# S32K146_M4 register map
Vendor: NXP Semiconductors; File version: 1.0
CPU: CM4 r0p1, little endian, MPU, FPU, VTOR, 4 interrupt priority bits
Registers are 32-bit, read-write, reset 0x0 unless marked. A register's access mark holds for its fields unless they carry their own. Offsets are from the block's base; [hi:lo] are bit positions; {n}, {i} and the like mark numbered series.

## FLEXCAN2 — CAN
Base 0x4002B000
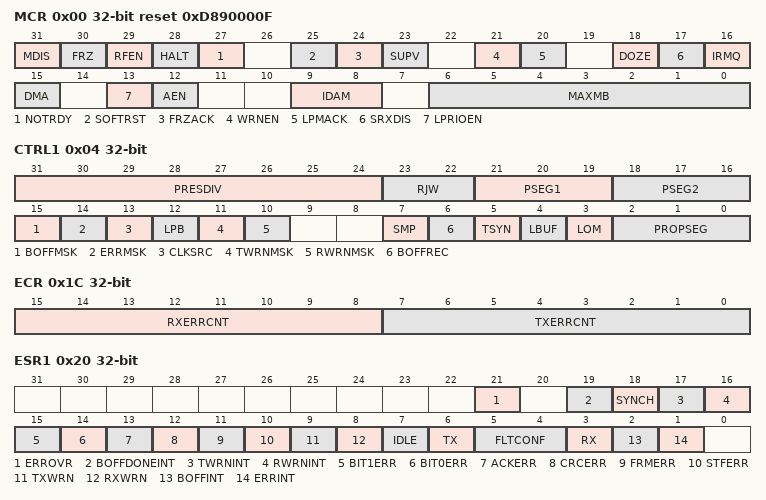
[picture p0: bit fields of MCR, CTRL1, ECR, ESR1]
0x00 MCR reset 0xD890000F — Module Configuration register
  [31] MDIS — Module Disable
    0=flexcan_enabled (Enable the FlexCAN module.); 1=flexcan_disabled (Disable the FlexCAN module.)
  [30] FRZ — Freeze Enable
    0=freeze_mode_disabled (Not enabled to enter Freeze mode.); 1=freeze_mode_enabled (Enabled to enter Freeze mode.)
  [29] RFEN — Rx FIFO Enable
    0=id2 (Rx FIFO not enabled.); 1=id4 (Rx FIFO enabled.)
  [28] HALT — Halt FlexCAN
    0=HALT_disable (No Freeze mode request.); 1=HALT_enable (Enters Freeze mode if the FRZ bit is asserted.)
  [27] NOTRDY ro — FlexCAN Not Ready
    0=id1 (FlexCAN module is either in Normal mode, Listen-Only mode, or Loop-Back mode.); 1=id2 (FlexCAN module is either in Disable mode, Doze mode, Stop mode, or Freeze mode.)
  [25] SOFTRST — Soft Reset
    0=SOFTRST_no_reset_request (No reset request.); 1=SOFTRST_reset_registers (Resets the registers affected by soft reset.)
  [24] FRZACK ro — Freeze Mode Acknowledge
    0=freeze_mode_no (FlexCAN not in Freeze mode, prescaler running.); 1=freeze_mode_yes (FlexCAN in Freeze mode, prescaler stopped.)
  [23] SUPV — Supervisor Mode
    0=id2 (FlexCAN is in User mode. Affected registers allow both Supervisor and Unrestricted accesses.); 1=id4 (FlexCAN is in Supervisor mode. Affected registers allow only Supervisor access. Unrestricted access behaves as though the access was done to an unimplemented register location.)
  [21] WRNEN — Warning Interrupt Enable
    0=TWRNINT_RWRNINT_inactive (TWRNINT and RWRNINT bits are zero, independent of the values in the error counters.); 1=TWRNINT_RWRNINT_active (TWRNINT and RWRNINT bits are set when the respective error counter transitions from less than 96 to greater than or equal to 96.)
  [20] LPMACK ro — Low-Power Mode Acknowledge
    0=low_power_no (FlexCAN is not in a low-power mode.); 1=low_power_yes (FlexCAN is in a low-power mode.)
  [18] DOZE — Doze Mode Enable
    0=low_power_doze_disabled (FlexCAN is not enabled to enter low-power mode when Doze mode is requested.); 1=low_power_doze_enabled (FlexCAN is enabled to enter low-power mode when Doze mode is requested.)
  [17] SRXDIS — Self Reception Disable
    0=self_reception_enabled; 1=self_reception_disabled
  [16] IRMQ — Individual Rx Masking And Queue Enable
    0=individual_rx_masking_disabled (Individual Rx masking and queue feature are disabled. For backward compatibility with legacy applications, the reading of C/S word locks the MB even if it is EMPTY.); 1=individual_rx_masking_enabled (Individual Rx masking and queue feature are enabled.)
  [15] DMA — DMA Enable
    0=id2 (DMA feature for RX FIFO disabled.); 1=id4 (DMA feature for RX FIFO enabled.)
  [13] LPRIOEN — Local Priority Enable
    0=local_priority_disabled; 1=local_priority_enabled
  [12] AEN — Abort Enable
    0=abort_disabled; 1=abort_enabled
  [9:8] IDAM — ID Acceptance Mode
    0=one_full_ID (Format A: One full ID (standard and extended) per ID filter table element.); 1=two_full_ID (Format B: Two full standard IDs or two partial 14-bit (standard and extended) IDs per ID filter table element.); 2=four_partial_ID (Format C: Four partial 8-bit standard IDs per ID filter table element.); 3=all_frames_rejected (Format D: All frames rejected.)
  [6:0] MAXMB — Number Of The Last Message Buffer
0x04 CTRL1 — Control 1 register
  [31:24] PRESDIV — Prescaler Division Factor
  [23:22] RJW — Resync Jump Width
  [21:19] PSEG1 — Phase Segment 1
  [18:16] PSEG2 — Phase Segment 2
  [15] BOFFMSK — Bus Off Interrupt Mask
    0=bus_off_int_disabled (Bus Off interrupt disabled.); 1=bus_off_int_enabled (Bus Off interrupt enabled.)
  [14] ERRMSK — Error Interrupt Mask
    0=error_int_disabled (Error interrupt disabled.); 1=error_int_enabled (Error interrupt enabled.)
  [13] CLKSRC — CAN Engine Clock Source
    0=oscillator_clock (The CAN engine clock source is the oscillator clock. Under this condition, the oscillator clock frequency must be lower than the bus clock.); 1=peripheral_clock (The CAN engine clock source is the peripheral clock.)
  [12] LPB — Loop Back Mode
    0=loopback_disabled; 1=loopback_enabled
  [11] TWRNMSK — Tx Warning Interrupt Mask
    0=tx_warning_int_disabled (Tx Warning interrupt disabled.); 1=tx_warning_int_enabled (Tx Warning interrupt enabled.)
  [10] RWRNMSK — Rx Warning Interrupt Mask
    0=rx_warning_int_disabled (Rx Warning interrupt disabled.); 1=rx_warning_int_enabled (Rx Warning interrupt enabled.)
  [7] SMP — CAN Bit Sampling
    0=one_sample (Just one sample is used to determine the bit value.); 1=Three samples are used to determine the value of the received bit: the regular one (sample point) and two preceding samples; a majority rule is used
  [6] BOFFREC — Bus Off Recovery
    0=auto_recover_enabled (Automatic recovering from Bus Off state enabled.); 1=auto_recover_disabled (Automatic recovering from Bus Off state disabled.)
  [5] TSYN — Timer Sync
    0=timer_sync_disabled (Timer sync feature disabled); 1=timer_sync_enabled (Timer sync feature enabled)
  [4] LBUF — Lowest Buffer Transmitted First
    0=highest_buffer_first (Buffer with highest priority is transmitted first.); 1=lowest_buffer_first (Lowest number buffer is transmitted first.)
  [3] LOM — Listen-Only Mode
    0=listen_only_mode_disabled (Listen-Only mode is deactivated.); 1=listen_only_mode_enabled (FlexCAN module operates in Listen-Only mode.)
  [2:0] PROPSEG — Propagation Segment
0x08 TIMER — Free Running Timer
  [15:0] TIMER — Timer Value
0x10 RXMGMASK reset not defined — Rx Mailboxes Global Mask register
  [31:0] MG — Rx Mailboxes Global Mask Bits
0x14 RX14MASK reset not defined
  [31:0] RX14M — Rx Buffer 14 Mask Bits
0x18 RX15MASK reset not defined
  [31:0] RX15M — Rx Buffer 15 Mask Bits
0x1C ECR — Error Counter
  [15:8] RXERRCNT — Receive Error Counter
  [7:0] TXERRCNT — Transmit Error Counter
0x20 ESR1 — Error and Status 1 register
  [21] ERROVR write-1-clears — Error Overrun
    0=overrun_not_occurred (Overrun has not occurred.); 1=overrun_occurred (Overrun has occurred.)
  [19] BOFFDONEINT write-1-clears — Bus Off Done Interrupt
    0=bus_off_not_done (No such occurrence.); 1=bus_off_done (FlexCAN module has completed Bus Off process.)
  [18] SYNCH ro — CAN Synchronization Status
    0=CAN_bus_sync_no (FlexCAN is not synchronized to the CAN bus.); 1=CAN_bus_sync_yes (FlexCAN is synchronized to the CAN bus.)
  [17] TWRNINT write-1-clears — Tx Warning Interrupt Flag
    0=Tx_warning_int_no (No such occurrence.); 1=Tx_warning_int_yes (The Tx error counter transitioned from less than 96 to greater than or equal to 96.)
  [16] RWRNINT write-1-clears — Rx Warning Interrupt Flag
    0=Rx_warning_int_no (No such occurrence.); 1=Rx_warning_int_yes (The Rx error counter transitioned from less than 96 to greater than or equal to 96.)
  [15] BIT1ERR ro — Bit1 Error
    0=bit1_error_no (No such occurrence.); 1=bit1_error_yes (At least one bit sent as recessive is received as dominant.)
  [14] BIT0ERR ro — Bit0 Error
    0=bit0_error_no (No such occurrence.); 1=bit0_error_yes (At least one bit sent as dominant is received as recessive.)
  [13] ACKERR ro — Acknowledge Error
    0=ACK_error_no (No such occurrence.); 1=ACK_error_yes (An ACK error occurred since last read of this register.)
  [12] CRCERR ro — Cyclic Redundancy Check Error
    0=CRC_error_no (No such occurrence.); 1=CRC_error_yes (A CRC error occurred since last read of this register.)
  [11] FRMERR ro — Form Error
    0=form_error_no (No such occurrence.); 1=form_error_yes (A Form Error occurred since last read of this register.)
  [10] STFERR ro — Stuffing Error
    0=stuffing_error_no (No such occurrence.); 1=stuffing_error_yes (A stuffing error occurred since last read of this register.)
  [9] TXWRN ro — TX Error Warning
    0=TXERRCNT_LT_96 (No such occurrence.); 1=TXERRCNT_GTE_96 (TXERRCNT is greater than or equal to 96.)
  [8] RXWRN ro — Rx Error Warning
    0=RXERRCNT_LT_96 (No such occurrence.); 1=RXERRCNT_GTE_96 (RXERRCNT is greater than or equal to 96.)
  [7] IDLE ro
    0=can_bus_not_idle (No such occurrence.); 1=can_bus_idle (CAN bus is now IDLE.)
  [6] TX ro — FlexCAN In Transmission
    0=transmit_message_no (FlexCAN is not transmitting a message.); 1=transmit_message_yes (FlexCAN is transmitting a message.)
  [5:4] FLTCONF ro — Fault Confinement State
    0=error_active; 1=error_passive; 0b1x=bus_off
  [3] RX ro — FlexCAN In Reception
    0=DISABLE (FlexCAN is not receiving a message.); 1=ENABLE (FlexCAN is receiving a message.)
  [2] BOFFINT write-1-clears — Bus Off Interrupt
    0=DISABLE (No such occurrence.); 1=ENABLE (FlexCAN module entered Bus Off state.)
  [1] ERRINT write-1-clears — Error Interrupt
    0=DISABLE (No such occurrence.); 1=ENABLE (Indicates setting of any error bit in the Error and Status register.)
0x28 IMASK1 — Interrupt Masks 1 register
  [15:0] BUF15TO0M — Buffer MB i Mask
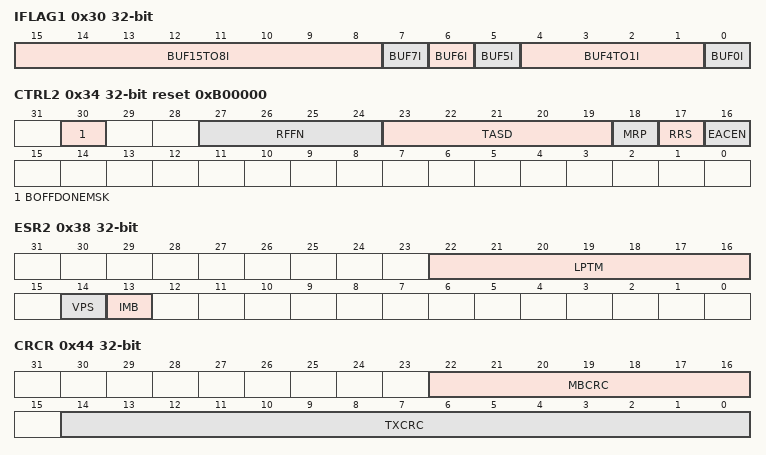
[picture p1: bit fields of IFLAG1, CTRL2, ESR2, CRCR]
0x30 IFLAG1 — Interrupt Flags 1 register
  [15:8] BUF15TO8I write-1-clears — Buffer MBi Interrupt
  [7] BUF7I write-1-clears — Buffer MB7 Interrupt Or Rx FIFO Overflow
    0=id2 (No occurrence of MB7 completing transmission/reception when MCR[RFEN]=0, or of Rx FIFO overflow when MCR[RFEN]=1); 1=id4 (MB7 completed transmission/reception when MCR[RFEN]=0, or Rx FIFO overflow when MCR[RFEN]=1)
  [6] BUF6I write-1-clears — Buffer MB6 Interrupt Or Rx FIFO Warning
    0=id2 (No occurrence of MB6 completing transmission/reception when MCR[RFEN]=0, or of Rx FIFO almost full when MCR[RFEN]=1); 1=id4 (MB6 completed transmission/reception when MCR[RFEN]=0, or Rx FIFO almost full when MCR[RFEN]=1)
  [5] BUF5I write-1-clears — Buffer MB5 Interrupt Or Frames available in Rx FIFO
    0=id2 (No occurrence of MB5 completing transmission/reception when MCR[RFEN]=0, or of frame(s) available in the FIFO, when MCR[RFEN]=1); 1=id4 (MB5 completed transmission/reception when MCR[RFEN]=0, or frame(s) available in the Rx FIFO when MCR[RFEN]=1. It generates a DMA request in case of MCR[RFEN] and MCR[DMA] are enabled.)
  [4:1] BUF4TO1I write-1-clears — Buffer MB i Interrupt Or Reserved
  [0] BUF0I write-1-clears — Buffer MB0 Interrupt Or Clear FIFO bit
    0=buffer_Tx_Rx_not_complete (The corresponding buffer has no occurrence of successfully completed transmission or reception when MCR[RFEN]=0.); 1=buffer_Tx_Rx_complete (The corresponding buffer has successfully completed transmission or reception when MCR[RFEN]=0.)
0x34 CTRL2 reset 0xB00000 — Control 2 register
  [30] BOFFDONEMSK — Bus Off Done Interrupt Mask
    0=DISABLE (Bus off done interrupt disabled.); 1=ENABLE (Bus off done interrupt enabled.)
  [27:24] RFFN — Number Of Rx FIFO Filters
  [23:19] TASD — Tx Arbitration Start Delay
  [18] MRP — Mailboxes Reception Priority
    0=id2 (Matching starts from Rx FIFO or Enhanced Rx FIFO and continues on mailboxes.); 1=id4 (Matching starts from mailboxes and continues on Rx FIFO.)
  [17] RRS — Remote Request Storing
    0=remote_response_frame_not_generated (Remote response frame is generated.); 1=remote_response_frame_generated (Remote request frame is stored.)
  [16] EACEN — Entire Frame Arbitration Field Comparison Enable For Rx Mailboxes
    0=RTR_compare_no (Rx mailbox filter's IDE bit is always compared and RTR is never compared despite mask bits.); 1=RTR_compare_yes (Enables the comparison of both Rx mailbox filter's IDE and RTR bit with their corresponding bits within the incoming frame. Mask bits do apply.)
0x38 ESR2 ro — Error and Status 2 register
  [22:16] LPTM — Lowest Priority Tx Mailbox
  [14] VPS — Valid Priority Status
    0=invalid (Contents of IMB and LPTM are invalid.); 1=valid (Contents of IMB and LPTM are valid.)
  [13] IMB — Inactive Mailbox
    0=inactive_mailbox_no (If ESR2[VPS] is asserted, the ESR2[LPTM] is not an inactive mailbox.); 1=inactive_mailbox_yes (If ESR2[VPS] is asserted, there is at least one inactive mailbox. LPTM content is the number of the first one.)
0x44 CRCR ro — CRC register
  [22:16] MBCRC — CRC Mailbox
  [14:0] TXCRC — Transmitted CRC value
0x48 RXFGMASK reset not defined — Rx FIFO Global Mask register
  [31:0] FGM — Rx FIFO Global Mask Bits
0x4C RXFIR ro reset not defined — Rx FIFO Information register
  [8:0] IDHIT — Identifier Acceptance Filter Hit Indicator
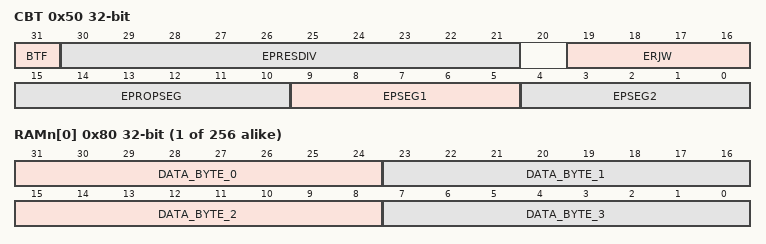
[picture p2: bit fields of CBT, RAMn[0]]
0x50 CBT — CAN Bit Timing register
  [31] BTF — Bit Timing Format Enable
    0=DISABLE (Extended bit time definitions disabled.); 1=ENABLE (Extended bit time definitions enabled.)
  [30:21] EPRESDIV — Extended Prescaler Division Factor
  [19:16] ERJW — Extended Resync Jump Width
  [15:10] EPROPSEG — Extended Propagation Segment
  [9:5] EPSEG1 — Extended Phase Segment 1
  [4:0] EPSEG2 — Extended Phase Segment 2
{0x80+4i} RAMn[{i}] (i=0..255) — Embedded RAM
  [31-8n:24-8n] DATA_BYTE_{n} (n=0..3) — Data byte {n} of Rx/Tx frame.
{0x880+4i} RXIMR[{i}] (i=0..15) reset not defined — Rx Individual Mask registers
  [31:0] MI — Individual Mask Bits

## Notices in the file
Copyright 2016-2021 NXP
NXP Confidential. This software is owned or controlled by NXP and may only be
used strictly in accordance with the applicable license terms. By expressly
accepting such terms or by downloading, installing, activating and/or otherwise
using the software, you are agreeing that you have read, and that you agree to
comply with and are bound by, such license terms. If you do not agree to be
bound by the applicable license terms, then you may not retain, install,
activate or otherwise use the software. The production use license in
Section 2.3 is expressly granted for this software.
